# GD32H71x_72x register map
File version: 1.0
CPU: CM7 r1p2, little endian, MPU, FPU, 4 interrupt priority bits
Registers are 32-bit, read-write, reset 0x0 unless marked. A register's access mark holds for its fields unless they carry their own. Offsets are from the block's base; [hi:lo] are bit positions; {n}, {i} and the like mark numbered series; 'fields as' and 'values as' point back to an identical list.

## EXMC — External memory controller
Base 0x52004000
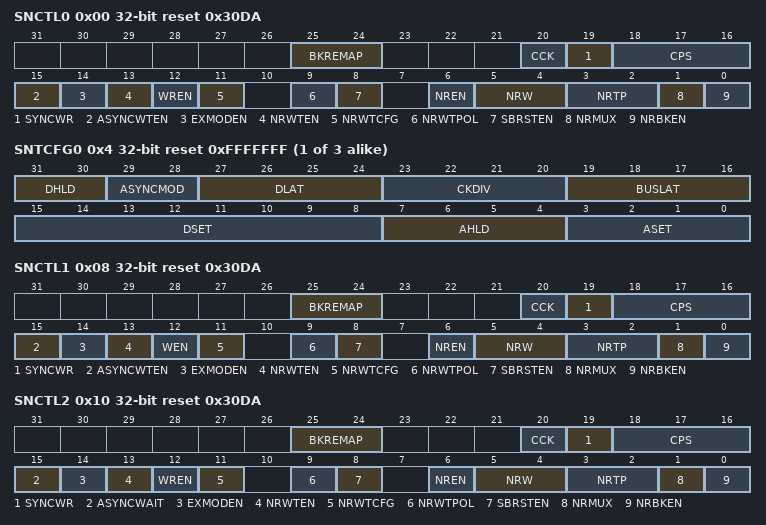
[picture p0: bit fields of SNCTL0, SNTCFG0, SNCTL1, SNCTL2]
0x00 SNCTL0 reset 0x30DA — SRAM/NOR flash control register 0
  [25:24] BKREMAP — Bank remap
  [20] CCK — Consecutive Clock
  [19] SYNCWR — Synchronous write
  [18:16] CPS — CRAM page size
  [15] ASYNCWTEN — Asynchronous wait enable
  [14] EXMODEN — Extended mode enable
  [13] NRWTEN — NWAIT signal enable
  [12] WREN — Write enable
  [11] NRWTCFG — NWAIT signal configuration, only work in synchronous mode
  [9] NRWTPOL — NWAIT signal polarity
  [8] SBRSTEN — Synchronous burst enable
  [6] NREN — NOR Flash access enable
  [5:4] NRW — NOR region memory data bus width
  [3:2] NRTP — NOR region memory type
  [1] NRMUX — NOR region memory address/data multiplexing
  [0] NRBKEN — NOR region enable
{0x4+8i} SNTCFG{i} reset 0xFFFFFFF (i=0..2) — SRAM/NOR flash timing configuration registe {i}
  [31:30] DHLD — Data hold time
  [29:28] ASYNCMOD — Asynchronous access mode
  [27:24] DLAT — Data latency for NOR Flash
  [23:20] CKDIV — Synchronous clock divide ratio
  [19:16] BUSLAT — Bus latency
  [15:8] DSET — Data setup time
  [7:4] AHLD — Address hold time
  [3:0] ASET — Address setup time
0x08 SNCTL1 reset 0x30DA — SRAM/NOR flash control registe 1
  [25:24] BKREMAP — Bank remap
  [20] CCK — Consecutive Clock
  [19] SYNCWR — Synchronous write
  [18:16] CPS — CRAM page size
  [15] ASYNCWTEN — Asynchronous wait
  [14] EXMODEN — Extended mode enable
  [13] NRWTEN — NWAIT signal enable
  [12] WEN — Write enable
  [11] NRWTCFG — NWAIT signal configuration, only work in synchronous mode
  [9] NRWTPOL — NWAIT signal polarity
  [8] SBRSTEN — Synchronous burst enable
  [6] NREN — NOR Flash access enable
  [5:4] NRW — NOR region memory data bus width
  [3:2] NRTP — NOR region memory type
  [1] NRMUX — NOR region memory address/data multiplexing
  [0] NRBKEN — NOR region enable
0x10 SNCTL2 reset 0x30DA — SRAM/NOR flash control registe 2
  [25:24] BKREMAP — Bank remap
  [20] CCK — Consecutive Clock
  [19] SYNCWR — Synchronous write
  [18:16] CPS — CRAM page size
  [15] ASYNCWAIT — Asynchronous wait
  [14] EXMODEN — Extended mode enable
  [13] NRWTEN — NWAIT signal enable
  [12] WREN — Write enable
  [11] NRWTCFG — NWAIT signal configuration, only work in synchronous mode
  [9] NRWTPOL — NWAIT signal polarity
  [8] SBRSTEN — Synchronous burst enable
  [6] NREN — NOR Flash access enable
  [5:4] NRW — NOR region memory data bus width
  [3:2] NRTP — NOR region memory type
  [1] NRMUX — NOR region memory address/data multiplexing
  [0] NRBKEN — NOR region enable
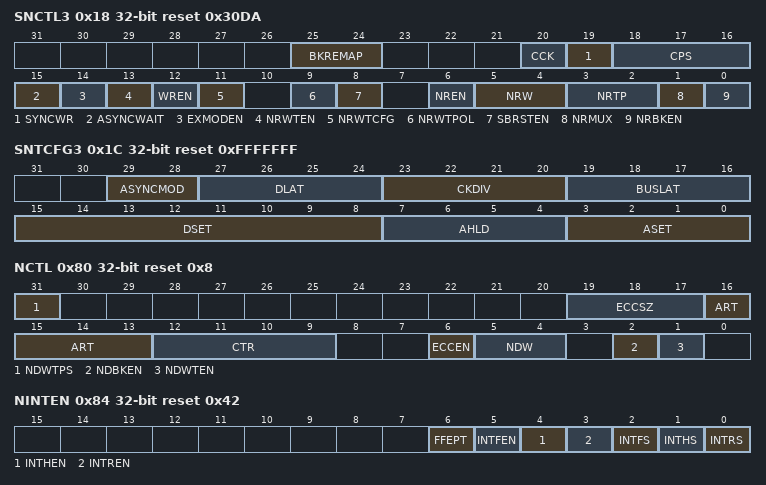
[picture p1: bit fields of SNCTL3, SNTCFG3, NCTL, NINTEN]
0x18 SNCTL3 reset 0x30DA — SRAM/NOR flash control registe 3
  fields as SNCTL2
0x1C SNTCFG3 reset 0xFFFFFFF — SRAM/NOR flash timing configuration registe 3
  [29:28] ASYNCMOD — Asynchronous access mode
  [27:24] DLAT — Data latency for NOR Flash
  [23:20] CKDIV — Synchronous clock divide ratio
  [19:16] BUSLAT — Bus latency
  [15:8] DSET — Data setup time
  [7:4] AHLD — Address hold time
  [3:0] ASET — Address setup time
0x80 NCTL reset 0x8 — NAND flash control registers
  [31] NDWTPS — NAND NWAIT pin select
  [19:17] ECCSZ — ECC size
  [16:13] ART — ALE to RE delay
  [12:9] CTR — CLE to RE delay
  [6] ECCEN — ECC enable
  [5:4] NDW — NAND bank memory data bus width
  [2] NDBKEN — NAND bank enable
  [1] NDWTEN — Wait function enable
0x84 NINTEN reset 0x42 — NAND flash interrupt enable registers
  [6] FFEPT — FIFO empty flag
  [5] INTFEN — Interrupt falling edge detection enable
  [4] INTHEN — Interrupt high-level detection enable
  [3] INTREN — Interrupt rising edge detection enable bit
  [2] INTFS — Interrupt falling edge status
  [1] INTHS — Interrupt high-level status
  [0] INTRS — Interrupt rising edge status
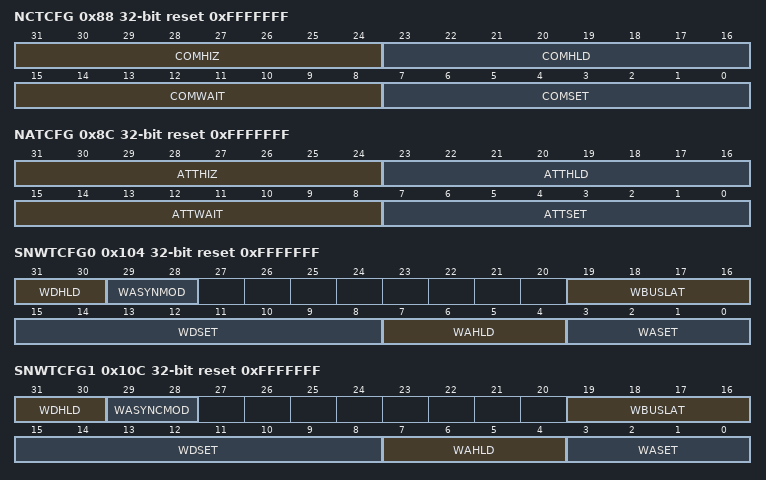
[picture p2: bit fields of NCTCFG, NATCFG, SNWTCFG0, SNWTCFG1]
0x88 NCTCFG reset 0xFFFFFFF — NAND flash common space timing configuration registers
  [31:24] COMHIZ — Common memory data bus HiZ time
  [23:16] COMHLD — Common memory hold time
  [15:8] COMWAIT — Common memory wait time
  [7:0] COMSET — Common memory setup time
0x8C NATCFG reset 0xFFFFFFF — NAND flash attribute space timing configuration registers
  [31:24] ATTHIZ — Attribute memory data bus HiZ time
  [23:16] ATTHLD — Attribute memory hold time
  [15:8] ATTWAIT — Attribute memory wait time
  [7:0] ATTSET — Attribute memory setup time
0x94 NECC ro — NAND flash ECC registers
  [31:0] ECC — ECC result
0x104 SNWTCFG0 reset 0xFFFFFFF — SRAM/NOR flash write timing configuration registe 0
  [31:30] WDHLD — Data hold time
  [29:28] WASYNMOD — Asynchronous access mode
  [19:16] WBUSLAT — Bus latency
  [15:8] WDSET — Data setup time
  [7:4] WAHLD — Address hold time
  [3:0] WASET — Address setup time
0x10C SNWTCFG1 reset 0xFFFFFFF — SRAM/NOR flash write timing configuration registe 1
  [31:30] WDHLD — Data hold time
  [29:28] WASYNCMOD — Asynchronous access mode
  [19:16] WBUSLAT — Bus latency
  [15:8] WDSET — Data setup time
  [7:4] WAHLD — Address hold time
  [3:0] WASET — Address setup time
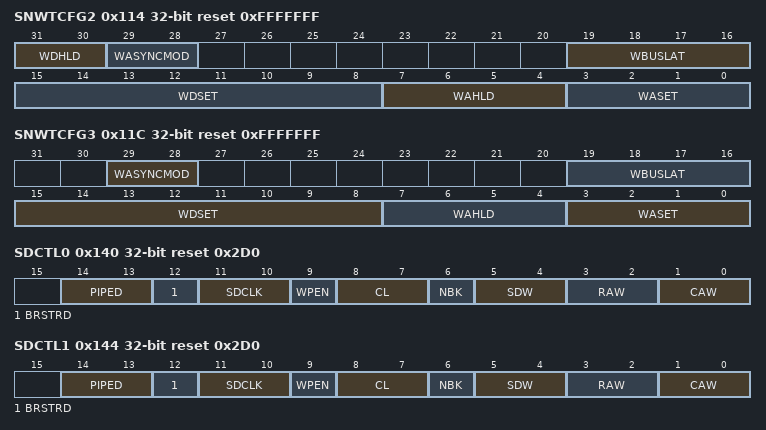
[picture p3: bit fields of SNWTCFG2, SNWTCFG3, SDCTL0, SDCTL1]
0x114 SNWTCFG2 reset 0xFFFFFFF — SRAM/NOR flash write timing configuration registe 2
  fields as SNWTCFG1
0x11C SNWTCFG3 reset 0xFFFFFFF — SRAM/NOR flash write timing configuration registe 3
  [29:28] WASYNCMOD — Asynchronous access mode
  [19:16] WBUSLAT — Bus latency
  [15:8] WDSET — Data setup time
  [7:4] WAHLD — Address hold time
  [3:0] WASET — Address setup time
0x140 SDCTL0 reset 0x2D0 — SDRAM control registe 0
  [14:13] PIPED — Pipeline delay
  [12] BRSTRD — Burst read
  [11:10] SDCLK — SDRAM clock configuration
  [9] WPEN — Write protection enable
  [8:7] CL — CAS Latency
  [6] NBK — Number of banks
  [5:4] SDW — SDRAM data bus width
  [3:2] RAW — Row address bit width
  [1:0] CAW — Column address bit width
0x144 SDCTL1 reset 0x2D0 — SDRAM control registe 1
  fields as SDCTL0
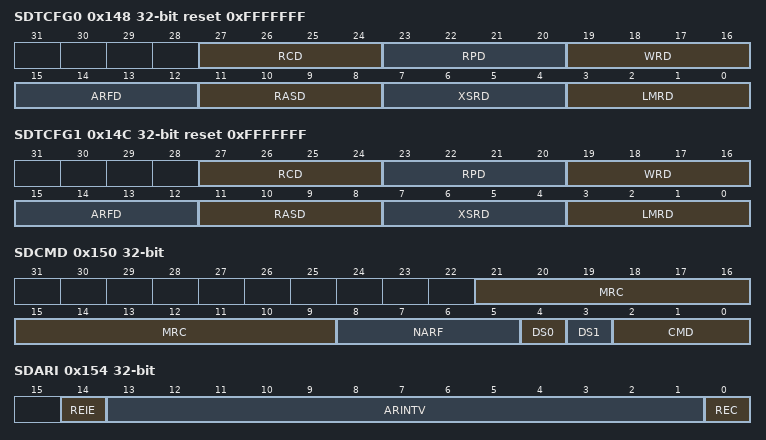
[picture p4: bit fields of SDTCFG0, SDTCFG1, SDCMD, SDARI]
0x148 SDTCFG0 reset 0xFFFFFFF — SDRAM timing configuration registe 0
  [27:24] RCD — Row to column delay
  [23:20] RPD — Row precharge delay
  [19:16] WRD — Write recovery delay
  [15:12] ARFD — Auto refresh delay
  [11:8] RASD — Row address select delay
  [7:4] XSRD — Exit Self-refresh delay
  [3:0] LMRD — Load Mode Register Delay
0x14C SDTCFG1 reset 0xFFFFFFF — SDRAM timing configuration registe 1
  fields as SDTCFG0
0x150 SDCMD — SDRAM command register
  [21:9] MRC — Mode register content
  [8:5] NARF — Number of successive Auto-refresh
  [4] DS0 — Device select 0
  [3] DS1 — Device select 1
  [2:0] CMD — Command
0x154 SDARI access per field — SDRAM auto-refresh interval register
  [14] REIE rw — Refresh error interrupt Enable
  [13:1] ARINTV rw — Auto-Refresh Interval
  [0] REC wo — Refresh error flag clear
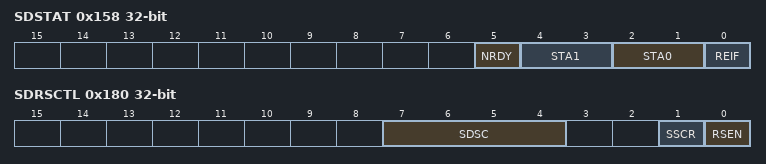
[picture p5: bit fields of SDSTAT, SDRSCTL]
0x158 SDSTAT ro — SDRAM status register
  [5] NRDY — Not Ready status
  [4:3] STA1 — Device1 status
  [2:1] STA0 — Device 0 status
  [0] REIF — Refresh error interrupt flag
0x15C SDRFCTL — SDRAM read fast control register
  [0] RFEN — Read fast mode enable
0x180 SDRSCTL — SDRAM read sample control register
  [7:4] SDSC — Select the delayed sample clock of read data
  [1] SSCR — Select sample cycle of read data
  [0] RSEN — Read sample enable
